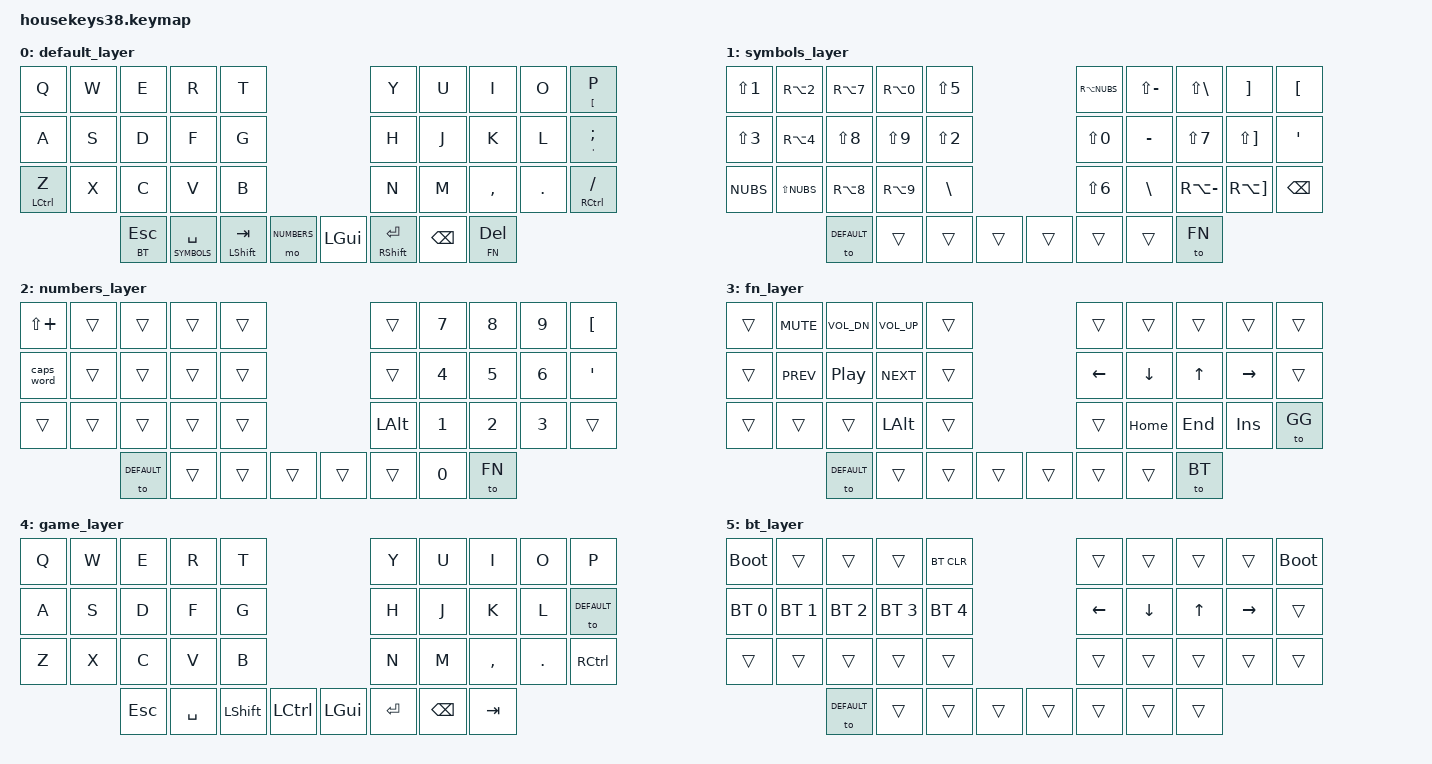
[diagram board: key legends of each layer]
#include <behaviors.dtsi>
#include <dt-bindings/zmk/keys.h>
#include <dt-bindings/zmk/bt.h>

#define DEFAULT     0
#define SYMBOLS     1
#define NUMBERS     2
#define FN          3
#define GG          4
#define BT          5


/ {
        behaviors {
            tt: this_or_that {
                compatible = "zmk,behavior-hold-tap";
                #binding-cells = <2>;
                tapping-term-ms = <135>;
                quick-tap-ms = <0>;
                flavor = "tap-preferred";
                bindings = <&kp>, <&kp>;
            };
        };

        keymap {
        compatible = "zmk,keymap";

        default_layer {
            bindings = <
                &kp Q       &kp W       &kp E       &kp R           &kp T                                               &kp Y           &kp U       &kp I           &kp O       &tt LBKT P
                &kp A       &kp S       &kp D       &kp F           &kp G                                               &kp H           &kp J       &kp K           &kp L       &tt SQT SEMI 
                &mt LCTRL Z &kp X       &kp C       &kp V           &kp B                                               &kp N           &kp M       &kp COMMA       &kp DOT     &mt RCTRL FSLH
                                        &lt BT ESC  &lt SYMBOLS SPACE&mt LSHFT TAB   &mo NUMBERS              &kp LGUI  &mt RSHIFT RETURN&kp BSPC   &lt FN DEL
            >;
        };

        symbols_layer {
            bindings = <
                &kp LS(N1)  &kp RA(N2)  &kp RA(N7)  &kp RA(N0)      &kp LS(N5)                                          &kp RA(NUBS)    &kp LS(MINUS)&kp LS(BSLH)   &kp RBKT    &kp LBKT
                &kp LS(N3)  &kp RA(N4)  &kp LS(N8)  &kp LS(N9)      &kp LS(N2)                                          &kp LS(N0)      &kp MINUS    &kp LS(N7)     &kp LS(RBKT)&kp SQT
                &kp NUBS    &kp LS(NUBS)&kp RA(N8)  &kp RA(N9)      &kp BSLH                                            &kp LS(N6)      &kp BSLH     &kp RA(MINUS)   &kp RA(RBKT)&kp BSPC
                                        &to DEFAULT &trans          &trans           &trans                &trans       &trans          &trans       &to FN
            >;
        };

        numbers_layer {
            bindings = <
                &kp LS(PLUS)&trans      &trans      &trans          &trans                                              &trans          &kp N7       &kp N8         &kp N9      &kp LBKT
                &caps_word  &trans      &trans      &trans          &trans                                              &trans          &kp N4       &kp N5         &kp N6      &kp SQT
                &trans      &trans      &trans      &trans          &trans                                              &kp LALT        &kp N1       &kp N2         &kp N3      &trans
                                        &to DEFAULT &trans          &trans           &trans                &trans       &trans          &kp N0       &to FN
            >;
        };
        
        fn_layer {
            bindings = <
                &trans      &kp C_MUTE  &kp C_VOL_DN&kp C_VOL_UP    &trans                                              &trans          &trans       &trans         &trans      &trans
                &trans      &kp C_PREV  &kp C_PP    &kp C_NEXT      &trans                                              &kp LEFT        &kp DOWN     &kp UP         &kp RIGHT   &trans
                &trans      &trans      &trans      &kp LALT        &trans                                              &trans          &kp HOME     &kp END        &kp INS     &to GG
                                        &to DEFAULT &trans          &trans           &trans                &trans       &trans          &trans       &to BT
            >;
        };

        game_layer {
            bindings = <
                &kp Q       &kp W       &kp E       &kp R           &kp T                                               &kp Y           &kp U       &kp I           &kp O       &kp P
                &kp A       &kp S       &kp D       &kp F           &kp G                                               &kp H           &kp J       &kp K           &kp L       &to DEFAULT
                &kp Z       &kp X       &kp C       &kp V           &kp B                                               &kp N           &kp M       &kp COMMA       &kp DOT     &kp RCTRL
                                        &kp ESC     &kp SPACE       &kp LSHFT       &kp LCTRL              &kp LGUI     &kp RETURN      &kp BSPC    &kp TAB
            >;
        };

        bt_layer {
            bindings = <
                &bootloader &trans      &trans      &trans          &bt BT_CLR                                          &trans          &trans       &trans         &trans      &bootloader
                &bt BT_SEL 0&bt BT_SEL 1&bt BT_SEL 2&bt BT_SEL 3    &bt BT_SEL 4                                        &kp LEFT        &kp DOWN     &kp UP         &kp RIGHT   &trans
                &trans      &trans      &trans      &trans          &trans                                              &trans          &trans       &trans         &trans      &trans
                                        &to DEFAULT &trans          &trans          &trans                 &trans       &trans          &trans       &trans
            >;
        };
    };
};
